# M251_v1 register map
File version: 1.0
Registers are 32-bit, read-write, reset 0x0 unless marked. A register's access mark holds for its fields unless they carry their own. Offsets are from the block's base; [hi:lo] are bit positions; 'fields as' and 'values as' point back to an identical list.

## USPI0 — USCISPI Register Map
Base 0x400D0000; alternate view of UUART0
0x00 USPI_CTL — USCI Control Register
  [2:0] FUNMODE — Function Mode. This bit field selects the protocol for this USCI controller. Selecting a protocol that is not available or a reserved combination disables the USCI. When switching between two protocols, the USCI has to be disabled before selecting a new protocol. Simultaneously, the USCI will be reset when user write 000 to FUNMODE. Note: Other bit combinations are reserved.
    0=The USCI is disabled. All protocol related state machines are set to idle state; 1=The SPI protocol is selected; 2=The UART protocol is selected; 4=The I2C protocol is selected
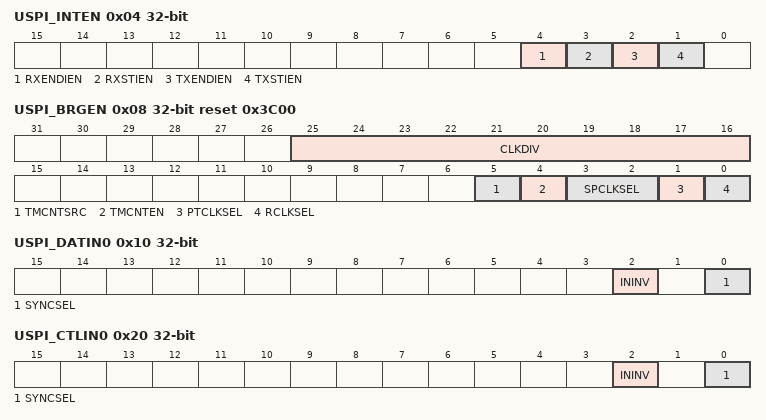
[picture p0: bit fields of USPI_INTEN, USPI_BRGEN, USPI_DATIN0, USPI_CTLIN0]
0x04 USPI_INTEN — USCI Interrupt Enable Register
  [4] RXENDIEN — Receive End Interrupt Enable Bit. This bit enables the interrupt generation in case of a receive finish event. Note: The receive finish event happens when hardware receives the last bit of RX data into shift data unit.
    0=The receive end interrupt Disabled; 1=The receive end interrupt Enabled
  [3] RXSTIEN — Receive Start Interrupt Enable Bit. This bit enables the interrupt generation in case of a receive start event. Note: For SPI master mode, the receive start event happens when SPI master sends slave select active and spi clock to the external SPI slave. For SPI slave mode, the receive start event happens when slave select of SPI slave is active and spi clock of SPI slave is inputed from the external SPI master.
    0=The receive start interrupt Disabled; 1=The receive start interrupt Enabled
  [2] TXENDIEN — Transmit End Interrupt Enable Bit. This bit enables the interrupt generation in case of a transmit finish event. Note: The transmit finish event happens when hardware sends the last bit of TX data from shift data unit.
    0=The transmit finish interrupt Disabled; 1=The transmit finish interrupt Enabled
  [1] TXSTIEN — Transmit Start Interrupt Enable Bit. This bit enables the interrupt generation in case of a transmit start event. Note: The transmit start event happens when hardware starts to move TX data from data buffer to shift data unit.
    0=The transmit start interrupt Disabled; 1=The transmit start interrupt Enabled
0x08 USPI_BRGEN reset 0x3C00 — USCI Baud Rate Generator Register
  [25:16] CLKDIV — Clock Divider
  [5] TMCNTSRC — Time Measurement Counter Clock Source Selection
    0=Time measurement counter with fPROT_CLK; 1=Time measurement counter with fDIV_CLK
  [4] TMCNTEN — Time Measurement Counter Enable Bit. This bit enables the 10-bit timing measurement counter.
    0=Time measurement counter Disabled; 1=Time measurement counter Enabled
  [3:2] SPCLKSEL — Sample Clock Source Selection. This bit field used for the clock source selection of sample clock (fSAMP_CLK) for the protocol processor.
    0=fDIV_CLK; 1=fPROT_CLK; 2=fSCLK; 3=fREF_CLK
  [1] PTCLKSEL — Protocol Clock Source Selection. This bit selects the source of protocol clock (fPROT_CLK).
    0=Reference clock fREF_CLK; 1=fREF_CLK2 (its frequency is half of fREF_CLK)
  [0] RCLKSEL — Reference Clock Source Selection. This bit selects the source of reference clock (fREF_CLK).
    0=Peripheral device clock fPCLK
0x10 USPI_DATIN0 — USCI Input Data Signal Configuration Register 0
  [2] ININV — Input Signal Inverse Selection. This bit defines the inverter enable of the input asynchronous signal. Note: In SPI protocol, it is suggested this bit should be set as 0.
    0=The un-synchronized input signal will not be inverted; 1=The un-synchronized input signal will be inverted
  [0] SYNCSEL — Input Signal Synchronization Selection. This bit selects if the un-synchronized input signal (with optionally inverted) or the synchronized (and optionally filtered) signal, which is synchronized with PCLK, can be used as input for the data shift unit. Note: In SPI protocol, it is suggested this bit should be set as 0.
    0=The un-synchronized signal can be taken as input for the data shift unit; 1=The synchronized signal can be taken as input for the data shift unit
0x20 USPI_CTLIN0 — USCI Input Control Signal Configuration Register 0
  [2] ININV — Input Signal Inverse Selection. This bit defines the inverter enable of the input asynchronous signal.
    values as USPI_DATIN0.ININV
  [0] SYNCSEL — Input Synchronization Signal Selection. This bit selects if the un-synchronized input signal (with optionally inverted) or the synchronized (and optionally filtered) signal, which is synchronized with PCLK, can be used as input for the data shift unit. Note: In SPI protocol, it is suggested this bit should be set as 0.
    values as USPI_DATIN0.SYNCSEL
0x28 USPI_CLKIN — USCI Input Clock Signal Configuration Register
  [0] SYNCSEL — Input Synchronization Signal Selection. This bit selects if the un-synchronized input signal or the synchronized (and optionally filtered) signal, which is synchronized with PCLK, can be used as input for the data shift unit. Note: In SPI protocol, it is suggested this bit should be set as 0.
    values as USPI_DATIN0.SYNCSEL
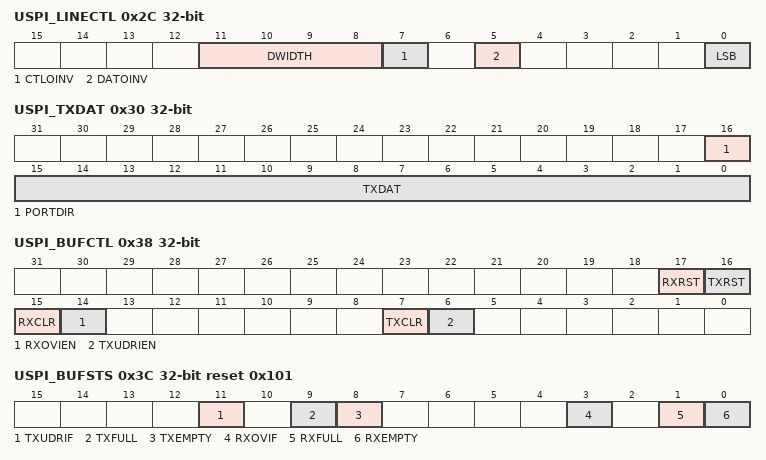
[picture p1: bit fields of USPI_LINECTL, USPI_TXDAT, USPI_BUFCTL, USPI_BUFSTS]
0x2C USPI_LINECTL — USCI Line Control Register
  [11:8] DWIDTH — Word Length of Transmission. This bit field defines the data word length (amount of bits) for reception and transmission. The data word is always right-aligned in the data buffer. USCI support word length from 4 to 16 bits. 0x0: The data word contains 16 bits located at bit positions [15:0]. 0x1: Reserved. 0x2: Reserved. 0x3: Reserved. 0x4: The data word contains 4 bits located at bit positions [3:0]. 0x5: The data word contains 5 bits located at bit positions [4:0]. ... 0xF: The data word contains 15 bits located at bit positions [14:0].
  [7] CTLOINV — Control Signal Output Inverse Selection. This bit defines the relation between the internal control signal and the output control signal. Note: The control signal has different definitions in different protocol. In SPI protocol, the control signal means slave select signal.
    0=No effect; 1=The control signal will be inverted before its output
  [5] DATOINV — Data Output Inverse Selection. This bit defines the relation between the internal shift data value and the output data signal of USCIx_DAT0/1 pin.
    0=Data output values of USCIx_DAT0/1 pins are not inverted; 1=Data output values of USCIx_DAT0/1 pins are inverted
  [0] LSB — LSB First Transmission Selection
    0=The MSB, which bit of transmit/receive data buffer depends on the setting of DWIDTH, is transmitted/received first; 1=The LSB, the bit 0 of data buffer, will be transmitted/received first
0x30 USPI_TXDAT wo — USCI Transmit Data Register
  [16] PORTDIR — Port Direction Control
    0=The data pin is configured as output mode; 1=The data pin is configured as input mode
  [15:0] TXDAT — Transmit Data. Software can use this bit field to write 16-bit transmit data for transmission. In order to avoid overwriting the transmit data, user have to check TXEMPTY (USPI_BUFSTS[8]) status before writing transmit data into this bit field.
0x34 USPI_RXDAT ro — USCI Receive Data Register
  [15:0] RXDAT — Received Data. This bit field monitors the received data which stored in receive data buffer.
0x38 USPI_BUFCTL — USCI Transmit/Receive Buffer Control Register
  [17] RXRST — Receive Reset. Note: It is cleared automatically after one PCLK cycle.
    0=No effect; 1=Reset the receive-related counters, state machine, and the content of receive shift register and data buffer
  [16] TXRST — Transmit Reset
    0=No effect; 1=Reset the transmit-related counters, state machine, and the content of transmit shift register and data buffer
  [15] RXCLR — Clear Receive Buffer. Note: It is cleared automatically after one PCLK cycle.
    0=No effect; 1=The receive buffer is cleared. Should only be used while the buffer is not taking part in data traffic
  [14] RXOVIEN — Receive Buffer Overrun Interrupt Enable Bit
    0=Receive overrun interrupt Disabled; 1=Receive overrun interrupt Enabled
  [7] TXCLR — Clear Transmit Buffer. Note: It is cleared automatically after one PCLK cycle.
    0=No effect; 1=The transmit buffer is cleared. Should only be used while the buffer is not taking part in data traffic
  [6] TXUDRIEN — Slave Transmit Under-run Interrupt Enable Bit
    0=Transmit under-run interrupt Disabled; 1=Transmit under-run interrupt Enabled
0x3C USPI_BUFSTS ro reset 0x101 — USCI Transmit/Receive Buffer Status Register
  [11] TXUDRIF — Transmit Buffer Under-run Interrupt Status. This bit indicates that a transmit buffer under-run event has been detected. If enabled by TXUDRIEN (USPI_BUFCTL[6]), the corresponding interrupt request is activated. It is cleared by software writes 1 to this bit
    0=A transmit buffer under-run event has not been detected; 1=A transmit buffer under-run event has been detected
  [9] TXFULL — Transmit Buffer Full Indicator
    0=Transmit buffer is not full; 1=Transmit buffer is full
  [8] TXEMPTY — Transmit Buffer Empty Indicator
    0=Transmit buffer is not empty; 1=Transmit buffer is empty and available for the next transmission datum
  [3] RXOVIF — Receive Buffer Over-run Interrupt Status. This bit indicates that a receive buffer overrun event has been detected. If RXOVIEN (USPI_BUFCTL[14]) is enabled, the corresponding interrupt request is activated. It is cleared by software writes 1 to this bit.
    0=A receive buffer overrun event has not been detected; 1=A receive buffer overrun event has been detected
  [1] RXFULL — Receive Buffer Full Indicator
    0=Receive buffer is not full; 1=Receive buffer is full
  [0] RXEMPTY — Receive Buffer Empty Indicator
    0=Receive buffer is not empty; 1=Receive buffer is empty
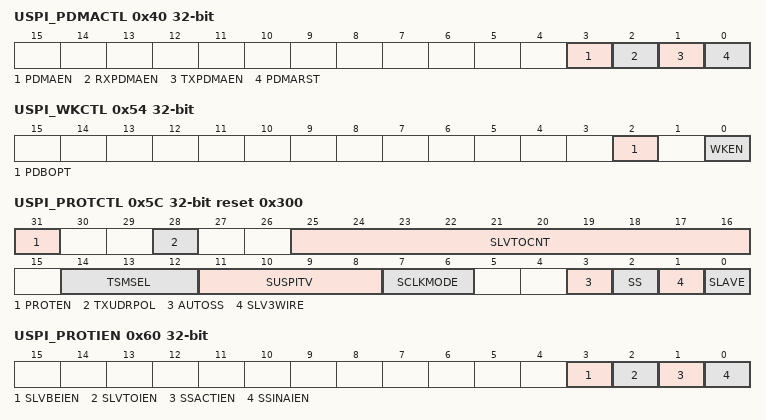
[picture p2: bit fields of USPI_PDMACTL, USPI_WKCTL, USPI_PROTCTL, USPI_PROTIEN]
0x40 USPI_PDMACTL — USCI PDMA Control Register
  [3] PDMAEN — PDMA Mode Enable Bit
    0=PDMA function Disabled; 1=PDMA function Enabled
  [2] RXPDMAEN — PDMA Receive Channel Available
    0=Receive PDMA function Disabled; 1=Receive PDMA function Enabled
  [1] TXPDMAEN — PDMA Transmit Channel Available
    0=Transmit PDMA function Disabled; 1=Transmit PDMA function Enabled
  [0] PDMARST — PDMA Reset
    0=No effect; 1=Reset the USCI's PDMA control logic. This bit will be cleared to 0 automatically
0x54 USPI_WKCTL — USCI Wake-up Control Register
  [2] PDBOPT — Power Down Blocking Option
    0=If user attempts to enter Power-down mode by executing WFI while the protocol is in transferring, MCU will stop the transfer and enter Power-down mode immediately; 1=If user attempts to enter Power-down mode by executing WFI while the protocol is in transferring, the on-going transfer will not be stopped and MCU will enter idle mode immediately
  [0] WKEN — Wake-up Enable Bit
    0=Wake-up function Disabled; 1=Wake-up function Enabled
0x58 USPI_WKSTS — USCI Wake-up Status Register
  [0] WKF — Wake-up Flag. When chip is woken up from Power-down mode, this bit is set to 1. Software can write 1 to clear this bit.
0x5C USPI_PROTCTL reset 0x300 — USCI Protocol Control Register
  [31] PROTEN — SPI Protocol Enable Bit
    0=SPI Protocol Disabled; 1=SPI Protocol Enabled
  [28] TXUDRPOL — Transmit Under-run Data Polarity (for Slave). This bit defines the transmitting data level of USCIx_DAT1 when no data is available for transferring.
    0=The output data level is 0 if TX under run event occurs; 1=The output data level is 1 if TX under run event occurs
  [25:16] SLVTOCNT — Slave Mode Time-out Period (Slave Only). In Slave mode, this bit field is used for Slave time-out period. This bit field indicates how many clock periods (selected by TMCNTSRC, USPI_BRGEN[5]) between the two edges of input SCLK will assert the Slave time-out event. Writing 0x0 into this bit field will disable the Slave time-out function. Example: Assume SLVTOCNT is 0x0A and TMCNTSRC (USPI_BRGEN[5]) is 1, it means the time-out event will occur if the state of SPI bus clock pin is not changed more than (10+1) periods of fDIV_CLK.
  [14:12] TSMSEL — Transmit Data Mode Selection. This bit field describes how receive and transmit data is shifted in and out. Note: Changing the value of this bit field will produce the TXRST and RXRST to clear the TX/RX data buffer automatically.
    0=TSMSEL: Full-duplex SPI; 4=TSMSEL: Half-duplex SPI
  [11:8] SUSPITV — Suspend Interval (Master Only). This bit field provides the configurable suspend interval between two successive transmit/receive transaction in a transfer. The definition of the suspend interval is the interval between the last clock edge of the preceding transaction word and the first clock edge of the following transaction word. The default value is 0x3. The period of the suspend interval is obtained according to the following equation. (SUSPITV + 0.5) * period of SPI_CLK clock cycle. Example:
  [7:6] SCLKMODE — Serial Bus Clock Mode. This bit field defines the SCLK idle status, data transmit, and data receive edge.
    0=MODE0. The idle state of SPI clock is low level. Data is transmitted with falling edge and received with rising edge; 1=MODE1. The idle state of SPI clock is low level. Data is transmitted with rising edge and received with falling edge; 2=MODE2. The idle state of SPI clock is high level. Data is transmitted with rising edge and received with falling edge; 3=MODE3. The idle state of SPI clock is high level. Data is transmitted with falling edge and received with rising edge
  [3] AUTOSS — Automatic Slave Select Function Enable (Master Only)
    0=Slave select signal will be controlled by the setting value of SS (USPI_PROTCTL[2]) bit; 1=Slave select signal will be generated automatically. The slave select signal will be asserted by the SPI controller when transmit/receive is started, and will be de-asserted after each transmit/receive is finished
  [2] SS — Slave Select Control (Master Only). If AUTOSS bit is cleared, setting this bit to 1 will set the slave select signal to active state, and setting this bit to 0 will set the slave select signal back to inactive state. Note: In SPI protocol, the internal slave select signal is active high.
  [1] SLV3WIRE — Slave 3-wire Mode Selection (Slave Only). The SPI protocol can work with 3-wire interface (without slave select signal) in Slave mode.
    0=4-wire bi-direction interface; 1=3-wire bi-direction interface
  [0] SLAVE — Slave Mode Selection
    0=Master mode; 1=Slave mode
0x60 USPI_PROTIEN — USCI Protocol Interrupt Enable Register
  [3] SLVBEIEN — Slave Mode Bit Count Error Interrupt Enable Bit. If data transfer is terminated by slave time-out or slave select inactive event in Slave mode, so that the transmit/receive data bit count does not match the setting of DWIDTH (USPI_LINECTL[11:8]). Bit count error event occurs.
    0=The Slave mode bit count error interrupt Disabled; 1=The Slave mode bit count error interrupt Enabled
  [2] SLVTOIEN — Slave Time-out Interrupt Enable Bit. In SPI protocol, this bit enables the interrupt generation in case of a Slave time-out event.
    0=The Slave time-out interrupt Disabled; 1=The Slave time-out interrupt Enabled
  [1] SSACTIEN — Slave Select Active Interrupt Enable Bit. This bit enables/disables the generation of a slave select interrupt if the slave select changes to active.
    0=Slave select active interrupt generation Disabled; 1=Slave select active interrupt generation Enabled
  [0] SSINAIEN — Slave Select Inactive Interrupt Enable Bit. This bit enables/disables the generation of a slave select interrupt if the slave select changes to inactive.
    0=Slave select inactive interrupt generation Disabled; 1=Slave select inactive interrupt generation Enabled
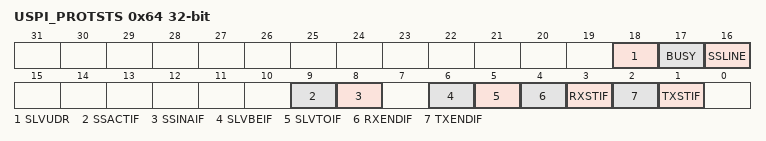
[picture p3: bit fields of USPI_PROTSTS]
0x64 USPI_PROTSTS — USCI Protocol Status Register
  [18] SLVUDR ro — Slave Mode Transmit Under-run Status (Read Only). In Slave mode, if there is no available transmit data in buffer while transmit data shift out caused by input serial bus clock, this status flag will be set to 1. This bit indicates whether the current shift-out data of word transmission is switched to TXUDRPOL (USPI_PROTCTL[28]) or not.
    0=Slave transmit under-run event does not occur; 1=Slave transmit under-run event occurs
  [17] BUSY ro — Busy Status (Read Only)
    0=SPI is in idle state; 1=SPI is in busy state
  [16] SSLINE ro — Slave Select Line Bus Status (Read Only). This bit is only available in Slave mode. It used to monitor the current status of the input slave select signal on the bus.
    0=The slave select line status is 0; 1=The slave select line status is 1
  [9] SSACTIF — Slave Select Active Interrupt Flag (for Slave Only). This bit indicates that the internal slave select signal has changed to active. It is cleared by software writes one to this bit. Note 1: The internal slave select signal is active high. Note 2: SSACTIF fix to 0 when slave 3-wire mode enable.
    0=The slave select signal has not changed to active; 1=The slave select signal has changed to active
  [8] SSINAIF — Slave Select Inactive Interrupt Flag (for Slave Only). This bit indicates that the internal slave select signal has changed to inactive. It is cleared by software writes 1 to this bit. Note 1: The internal slave select signal is active high. Note 2: SSINAIF fix to 0 when slave 3-wire mode enable.
    0=The slave select signal has not changed to inactive; 1=The slave select signal has changed to inactive
  [6] SLVBEIF — Slave Bit Count Error Interrupt Flag (for Slave Only). Note 1: It is cleared by software write 1 to this bit. If the transmit/receive data bit count does not match the setting of DWIDTH (USPI_LINECTL[11:8]), bit count error event occurs. Note 2: SLVBEIF fix to 0 when slave 3-wire mode enable.
    0=Slave bit count error event did not occur; 1=Slave bit count error event occurred
  [5] SLVTOIF — Slave Time-out Interrupt Flag (for Slave Only). Note: It is cleared by software write 1 to this bit
    0=Slave time-out event did not occur; 1=Slave time-out event occurred
  [4] RXENDIF — Receive End Interrupt Flag. Note: It is cleared by software write 1 to this bit. The receive end event happens when hardware receives the last bit of RX data into shift data unit.
    0=Receive end event did not occur; 1=Receive end event occurred
  [3] RXSTIF — Receive Start Interrupt Flag. Note: It is cleared by software write 1 to this bit. For SPI master mode, the receive start event happens when SPI master sends slave select active and spi clock to the external SPI slave. For SPI slave mode, the receive start event happens when slave select of SPI slave is active and spi clock of SPI slave is inputed from the external SPI master.
    0=Receive start event did not occur; 1=Receive start event occurred
  [2] TXENDIF — Transmit End Interrupt Flag. Note: It is cleared by software write 1 to this bit. The transmit end event happens when hardware sends the last bit of TX data from shift data unit.
    0=Transmit end event did not occur; 1=Transmit end event occurred
  [1] TXSTIF — Transmit Start Interrupt Flag. Note: It is cleared by software write 1 to this bit. The transmit start event happens when hardware starts to move TX data from data buffer to shift data unit.
    0=Transmit start event did not occur; 1=Transmit start event occurred

## USPI1 — USCISPI Register Map
Base 0x400D1000; alternate view of UUART1
Registers as USPI0.

## USPI2 — USCISPI Register Map
Base 0x400D2000; alternate view of UUART2
Registers as USPI0.
